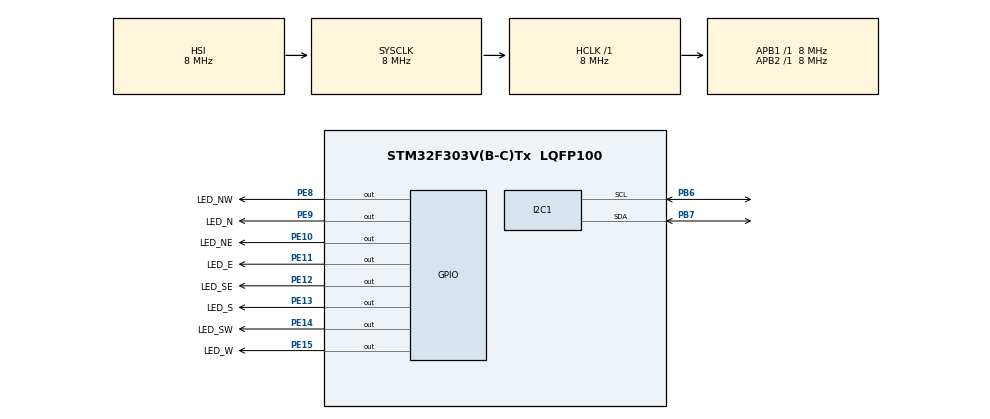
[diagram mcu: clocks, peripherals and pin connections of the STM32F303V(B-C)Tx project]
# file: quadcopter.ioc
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Mcu.Family=STM32F3
Mcu.Name=STM32F303V(B-C)Tx
Mcu.Package=LQFP100
NVIC.PriorityGroup=NVIC_PRIORITYGROUP_4
PB6.Mode=I2C
PB6.Signal=I2C1_SCL
PB7.Mode=I2C
PB7.Signal=I2C1_SDA
PE10.GPIO_Label=LED_NE
PE10.Signal=GPIO_Output
PE11.GPIO_Label=LED_E
PE11.Signal=GPIO_Output
PE12.GPIO_Label=LED_SE
PE12.Signal=GPIO_Output
PE13.GPIO_Label=LED_S
PE13.Signal=GPIO_Output
PE14.GPIO_Label=LED_SW
PE14.Signal=GPIO_Output
PE15.GPIO_Label=LED_W
PE15.Signal=GPIO_Output
PE8.GPIO_Label=LED_NW
PE8.Signal=GPIO_Output
PE9.GPIO_Label=LED_N
PE9.Signal=GPIO_Output
ProjectManager.HeapSize=0x200
ProjectManager.StackSize=0x400
ProjectManager.TargetToolchain=Makefile
RCC.AHBFreq_Value=8000000
RCC.APB1Freq_Value=8000000
RCC.APB2Freq_Value=8000000
RCC.CortexFreq_Value=8000000
RCC.HSE_VALUE=8000000
RCC.HSI_VALUE=8000000
RCC.LSE_VALUE=32768
RCC.SYSCLKFreq_VALUE=8000000
board=custom

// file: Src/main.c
/* USER CODE BEGIN Header */
/**
  ******************************************************************************
  * @file           : main.c
  * @brief          : Main program body
  ******************************************************************************
  * @attention
  *
  * <h2><center>&copy; Copyright (c) 2021 STMicroelectronics.
  * All rights reserved.</center></h2>
  *
  * This software component is licensed by ST under BSD 3-Clause license,
  * the "License"; You may not use this file except in compliance with the
  * License. You may obtain a copy of the License at:
  *                        opensource.org/licenses/BSD-3-Clause
  *
  ******************************************************************************
  */
/* USER CODE END Header */
#include "main.h"

I2C_HandleTypeDef hi2c1;

void SystemClock_Config(void);
static void MX_GPIO_Init(void);
static void MX_I2C1_Init(void);

void SystemClock_Config(void)
{
  RCC_OscInitTypeDef RCC_OscInitStruct = {0};
  RCC_ClkInitTypeDef RCC_ClkInitStruct = {0};
  RCC_PeriphCLKInitTypeDef PeriphClkInit = {0};

  /** Initializes the RCC Oscillators according to the specified parameters
  * in the RCC_OscInitTypeDef structure.
  */
  RCC_OscInitStruct.OscillatorType = RCC_OSCILLATORTYPE_HSI;
  RCC_OscInitStruct.HSIState = RCC_HSI_ON;
  RCC_OscInitStruct.HSICalibrationValue = RCC_HSICALIBRATION_DEFAULT;
  RCC_OscInitStruct.PLL.PLLState = RCC_PLL_NONE;
  if (HAL_RCC_OscConfig(&RCC_OscInitStruct) != HAL_OK)
  {
    Error_Handler();
  }
  /** Initializes the CPU, AHB and APB buses clocks
  */
  RCC_ClkInitStruct.ClockType = RCC_CLOCKTYPE_HCLK|RCC_CLOCKTYPE_SYSCLK
                              |RCC_CLOCKTYPE_PCLK1|RCC_CLOCKTYPE_PCLK2;
  RCC_ClkInitStruct.SYSCLKSource = RCC_SYSCLKSOURCE_HSI;
  RCC_ClkInitStruct.AHBCLKDivider = RCC_SYSCLK_DIV1;
  RCC_ClkInitStruct.APB1CLKDivider = RCC_HCLK_DIV1;
  RCC_ClkInitStruct.APB2CLKDivider = RCC_HCLK_DIV1;

  if (HAL_RCC_ClockConfig(&RCC_ClkInitStruct, FLASH_LATENCY_0) != HAL_OK)
  {
    Error_Handler();
  }
  PeriphClkInit.PeriphClockSelection = RCC_PERIPHCLK_I2C1;
  PeriphClkInit.I2c1ClockSelection = RCC_I2C1CLKSOURCE_HSI;
  if (HAL_RCCEx_PeriphCLKConfig(&PeriphClkInit) != HAL_OK)
  {
    Error_Handler();
  }
}

static void MX_I2C1_Init(void)
{

  hi2c1.Instance = I2C1;
  hi2c1.Init.Timing = 0x2000090E;
  hi2c1.Init.OwnAddress1 = 0;
  hi2c1.Init.AddressingMode = I2C_ADDRESSINGMODE_7BIT;
  hi2c1.Init.DualAddressMode = I2C_DUALADDRESS_DISABLE;
  hi2c1.Init.OwnAddress2 = 0;
  hi2c1.Init.OwnAddress2Masks = I2C_OA2_NOMASK;
  hi2c1.Init.GeneralCallMode = I2C_GENERALCALL_DISABLE;
  hi2c1.Init.NoStretchMode = I2C_NOSTRETCH_DISABLE;
  if (HAL_I2C_Init(&hi2c1) != HAL_OK)
  {
    Error_Handler();
  }
  /** Configure Analogue filter
  */
  if (HAL_I2CEx_ConfigAnalogFilter(&hi2c1, I2C_ANALOGFILTER_ENABLE) != HAL_OK)
  {
    Error_Handler();
  }
  /** Configure Digital filter
  */
  if (HAL_I2CEx_ConfigDigitalFilter(&hi2c1, 0) != HAL_OK)
  {
    Error_Handler();
  }

}

static void MX_GPIO_Init(void)
{
  GPIO_InitTypeDef GPIO_InitStruct = {0};

  /* GPIO Ports Clock Enable */
  __HAL_RCC_GPIOE_CLK_ENABLE();
  __HAL_RCC_GPIOB_CLK_ENABLE();

  /*Configure GPIO pin Output Level */
  HAL_GPIO_WritePin(GPIOE, LED_NW_Pin|LED_N_Pin|LED_NE_Pin|LED_E_Pin
                          |LED_SE_Pin|LED_S_Pin|LED_SW_Pin|LED_W_Pin, GPIO_PIN_RESET);

  /*Configure GPIO pins : LED_NW_Pin LED_N_Pin LED_NE_Pin LED_E_Pin
                           LED_SE_Pin LED_S_Pin LED_SW_Pin LED_W_Pin */
  GPIO_InitStruct.Pin = LED_NW_Pin|LED_N_Pin|LED_NE_Pin|LED_E_Pin
                          |LED_SE_Pin|LED_S_Pin|LED_SW_Pin|LED_W_Pin;
  GPIO_InitStruct.Mode = GPIO_MODE_OUTPUT_PP;
  GPIO_InitStruct.Pull = GPIO_NOPULL;
  GPIO_InitStruct.Speed = GPIO_SPEED_FREQ_LOW;
  HAL_GPIO_Init(GPIOE, &GPIO_InitStruct);

}

/* USER CODE BEGIN 4 */
void InitHardware(void)
{
  SystemClock_Config();
  MX_GPIO_Init();
  MX_I2C1_Init();
}
/* USER CODE END 4 */

void Error_Handler(void)
{
  __disable_irq();
  while (1)
  {
  }
}

/************************ (C) COPYRIGHT STMicroelectronics *****END OF FILE****/
